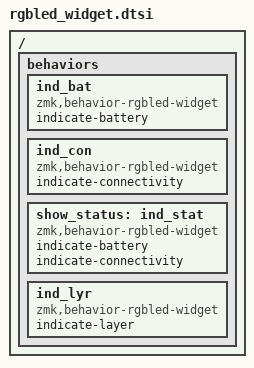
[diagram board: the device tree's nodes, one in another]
/ {
    behaviors {
        /omit-if-no-ref/ ind_bat: ind_bat {
            compatible = "zmk,behavior-rgbled-widget";
            #binding-cells = <0>;
            indicate-battery;
        };
        /omit-if-no-ref/ ind_con: ind_con {
            compatible = "zmk,behavior-rgbled-widget";
            #binding-cells = <0>;
            indicate-connectivity;
        };
        // Node name must be <= 8 chars: ZMK truncates behavior names to 8
        // chars when relaying global behaviors to split peripherals.
        /omit-if-no-ref/ show_status: ind_stat {
            compatible = "zmk,behavior-rgbled-widget";
            #binding-cells = <0>;
            indicate-battery;
            indicate-connectivity;
        };
        /omit-if-no-ref/ ind_lyr: ind_lyr {
            compatible = "zmk,behavior-rgbled-widget";
            #binding-cells = <0>;
            indicate-layer;
        };
    };
};
